VERSION ""

NS_ :

BS_:

BU_: Vector__XXX

BA_DEF_ SG_  "SPN" INT 0 524287;

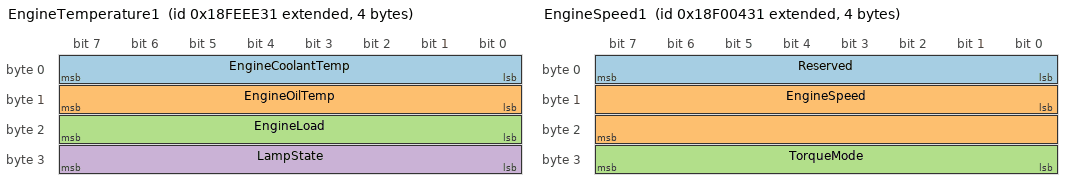
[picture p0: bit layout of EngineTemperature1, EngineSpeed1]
BO_ 2566843953 EngineTemperature1: 4 Vector__XXX
 SG_ EngineCoolantTemp : 0|8@1+ (1,-40) [0|210] "degC" Vector__XXX
 SG_ EngineOilTemp : 8|8@1+ (1,-40) [0|210] "degC" Vector__XXX
 SG_ EngineLoad : 16|8@1+ (0.4,0) [0|100] "%" Vector__XXX
 SG_ LampState : 24|8@1+ (1,0) [0|255] "" Vector__XXX

BO_ 2565866545 EngineSpeed1: 4 Vector__XXX
 SG_ Reserved : 0|8@1+ (1,0) [0|255] "" Vector__XXX
 SG_ EngineSpeed : 8|16@1+ (0.125,0) [0|8031.875] "rpm" Vector__XXX
 SG_ TorqueMode : 24|8@1+ (1,0) [0|255] "" Vector__XXX

BO_ 2565866546 EngineBitfield1: 4 Vector__XXX
 SG_ NibbleSignal : 4|12@1+ (1,0) [0|4095] "" Vector__XXX

BA_ "SPN" SG_ 2566843953 EngineCoolantTemp 110;
BA_ "SPN" SG_ 2566843953 EngineOilTemp 175;
BA_ "SPN" SG_ 2565866545 EngineSpeed 190;
BA_ "SPN" SG_ 2565866546 NibbleSignal 1234;
